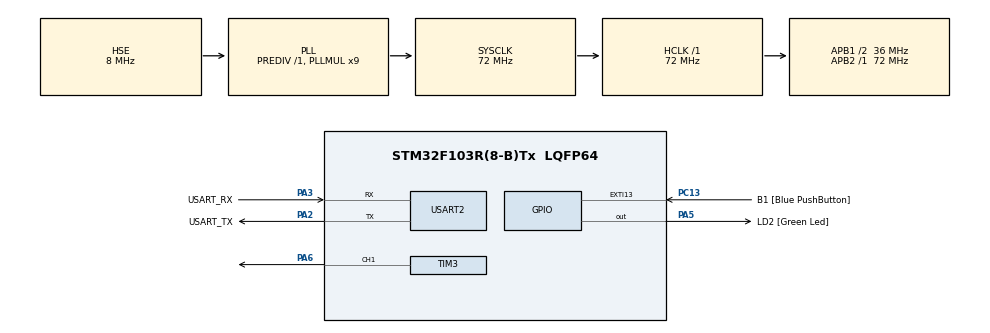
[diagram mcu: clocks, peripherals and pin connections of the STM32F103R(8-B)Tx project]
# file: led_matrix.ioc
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Dma.Request0=TIM3_CH1/TRIG
Dma.TIM3_CH1/TRIG.0.Direction=DMA_MEMORY_TO_PERIPH
Dma.TIM3_CH1/TRIG.0.Instance=DMA1_Channel6
Dma.TIM3_CH1/TRIG.0.MemDataAlignment=DMA_MDATAALIGN_BYTE
Dma.TIM3_CH1/TRIG.0.MemInc=DMA_MINC_ENABLE
Dma.TIM3_CH1/TRIG.0.Mode=DMA_NORMAL
Dma.TIM3_CH1/TRIG.0.PeriphDataAlignment=DMA_PDATAALIGN_HALFWORD
Dma.TIM3_CH1/TRIG.0.PeriphInc=DMA_PINC_DISABLE
Dma.TIM3_CH1/TRIG.0.Priority=DMA_PRIORITY_LOW
Mcu.Family=STM32F1
Mcu.Name=STM32F103R(8-B)Tx
Mcu.Package=LQFP64
NVIC.DMA1_Channel6_IRQn=true\:0\:0\:false\:false\:true\:false\:true\:true
NVIC.EXTI15_10_IRQn=true\:0\:0\:false\:false\:true\:true\:true\:true
NVIC.PriorityGroup=NVIC_PRIORITYGROUP_4
NimaLTD.I-CUBE-WS28XX.3.0.1.DriverJjWS28XX=true
PA13.GPIO_Label=TMS
PA13.Mode=Serial_Wire
PA13.Signal=SYS_JTMS-SWDIO
PA14.GPIO_Label=TCK
PA14.Mode=Serial_Wire
PA14.Signal=SYS_JTCK-SWCLK
PA2.GPIO_Label=USART_TX
PA2.GPIO_Mode=GPIO_MODE_AF_PP
PA2.GPIO_PuPd=GPIO_NOPULL
PA2.GPIO_Speed=GPIO_SPEED_FREQ_LOW
PA2.Mode=Asynchronous
PA2.Signal=USART2_TX
PA3.GPIO_Label=USART_RX
PA3.GPIO_Mode=GPIO_MODE_AF_PP
PA3.GPIO_PuPd=GPIO_NOPULL
PA3.GPIO_Speed=GPIO_SPEED_FREQ_LOW
PA3.Mode=Asynchronous
PA3.Signal=USART2_RX
PA5.GPIO_Label=LD2 [Green Led]
PA5.GPIO_ModeDefaultOutputPP=GPIO_MODE_OUTPUT_PP
PA5.GPIO_PuPd=GPIO_NOPULL
PA5.GPIO_Speed=GPIO_SPEED_FREQ_LOW
PA5.Signal=GPIO_Output
PA6.Signal=S_TIM3_CH1
PB3.GPIO_Label=SWO
PB3.Signal=SYS_JTDO-TRACESWO
PC13-TAMPER-RTC.GPIO_Label=B1 [Blue PushButton]
PC13-TAMPER-RTC.GPIO_PuPd=GPIO_NOPULL
PC13-TAMPER-RTC.Signal=GPXTI13
PC14-OSC32_IN.Mode=LSE-External-Oscillator
PC14-OSC32_IN.Signal=RCC_OSC32_IN
PC15-OSC32_OUT.Mode=LSE-External-Oscillator
PC15-OSC32_OUT.Signal=RCC_OSC32_OUT
PD0-OSC_IN.Mode=HSE-External-Clock-Source
PD0-OSC_IN.Signal=RCC_OSC_IN
PD1-OSC_OUT.Mode=HSE-External-Clock-Source
PD1-OSC_OUT.Signal=RCC_OSC_OUT
ProjectManager.HeapSize=0x200
ProjectManager.StackSize=0x400
ProjectManager.TargetToolchain=STM32CubeIDE
RCC.AHBFreq_Value=72000000
RCC.APB1CLKDivider=RCC_HCLK_DIV2
RCC.APB1Freq_Value=36000000
RCC.APB1TimFreq_Value=72000000
RCC.APB2Freq_Value=72000000
RCC.APB2TimFreq_Value=72000000
RCC.HCLKFreq_Value=72000000
RCC.PLLMUL=RCC_PLL_MUL9
RCC.PLLSourceVirtual=RCC_PLLSOURCE_HSE
RCC.RTCClockSelection=RCC_RTCCLKSOURCE_LSE
RCC.SYSCLKFreq_VALUE=72000000
RCC.SYSCLKSource=RCC_SYSCLKSOURCE_PLLCLK
RCC.USBFreq_Value=72000000
SH.S_TIM3_CH1.0=TIM3_CH1,PWM Generation1 CH1
TIM3.Channel-PWM\ Generation1\ CH1=TIM_CHANNEL_1
USART2.VirtualMode=VM_ASYNC
VP_NimaLTD.I-CUBE-WS28XX_VS_DriverJjWS28XX_1.0.0_3.0.1.Mode=DriverJjWS28XX
VP_TIM3_VS_ClockSourceINT.Mode=Internal
board=NUCLEO-F103RB

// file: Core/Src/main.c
/* USER CODE BEGIN Header */
/**
  ******************************************************************************
  * @file           : main.c
  * @brief          : Main program body
  ******************************************************************************
  * @attention
  *
  * Copyright (c) 2024 STMicroelectronics.
  * All rights reserved.
  *
  ******************************************************************************
  */
/* USER CODE END Header */
#include "main.h"
#include "dma.h"
#include "tim.h"
#include "usart.h"
#include "gpio.h"

/* USER CODE BEGIN Includes */
#include "ws28xx.h"
/* USER CODE END Includes */

#define LED_ROWS 8
#define LED_COLS 32
#define DELAY_TIME 50  // Faster shifting delay

WS28XX_HandleTypeDef ws;

/* Function to calculate the correct LED index based on the zig-zag pattern */
int Get_LED_Index(int row, int col) {
    if (row % 2 == 0) {
        // Even row (left-to-right)
        return (row * LED_COLS / 2) + col;
    } else {
        // Odd row (right-to-left)
        return (row * LED_COLS / 2) + (LED_COLS / 2 - 1 - col);
    }
}

/* Function to draw the arrow */
void Draw_Arrow(WS28XX_HandleTypeDef *ws, int *arrow, int color, int brightness) {
    for (int i = 0; i < 26; i++) {
        // Ensure arrow doesn't affect the first 2 rows or last 2 rows of the LED matrix (top and bottom strips)
        if (arrow[i] >= 16 && arrow[i] <= 239) {
            WS28XX_SetPixel_RGBW_565(ws, arrow[i], color, brightness);  // Only set pixels between the top and bottom strips
        }
    }
    WS28XX_Update(ws);  // Update the matrix to display the arrow
}

/* Function to clear the arrow */
void Clear_Arrow(WS28XX_HandleTypeDef *ws, int *arrow) {
    for (int i = 0; i < 26; i++) {
        if (arrow[i] >= 16 && arrow[i] <= 239) {
            WS28XX_SetPixel_RGBW_565(ws, arrow[i], COLOR_RGB565_BLACK, 0);  // Clear the arrow LEDs between the top and bottom strips
        }
    }
    WS28XX_Update(ws);  // Update the matrix to clear the arrow
}

/* Function to shift the arrow forward */
void Shift_Arrow(int *arrow) {
    for (int i = 0; i < 26; i++) {
        arrow[i] = arrow[i] + 8;  // Shifting each LED forward by one row (8 LEDs in each row)
        if (arrow[i] >= 240) {  // Reset the arrow to the starting position (after the bottom strip)
            arrow[i] = arrow[i] % (LED_ROWS * LED_COLS - 16);  // Ensure the arrow stays between rows 2 to 6
        }
    }
}

/* Function to draw the top and bottom strips */
void Draw_Strips(WS28XX_HandleTypeDef *ws, int color, int brightness) {
    // Top strip (LEDs from 240 to 255)
    for (int i = 240; i <= 255; i++) {
        WS28XX_SetPixel_RGBW_565(ws, i, color, brightness);
    }

    // Bottom strip (LEDs from 0 to 15)
    for (int i = 0; i <= 15; i++) {
        WS28XX_SetPixel_RGBW_565(ws, i, color, brightness);
    }

    WS28XX_Update(ws);  // Update the matrix to display the strips
}

/* Function to update brightness for both arrow and strips */
void Update_Brightness(WS28XX_HandleTypeDef *ws, int arrow_brightness, int strip_brightness) {
    // Arrow shape LED indices
    int arrow[] = {
        83, 84, 91, 92, 99, 100, 107, 108, 115, 116, 123, 124,
        131, 132, 137, 138, 139, 140, 141, 142, 146, 147, 148, 149,
        155, 156
    };

    // Update brightness for the arrow
    Draw_Arrow(ws, arrow, COLOR_RGB565_GREEN, arrow_brightness);

    // Update brightness for the strips
    Draw_Strips(ws, COLOR_RGB565_CYAN, strip_brightness);
}

/* The application entry point. */
int main(void) {
  /* MCU Configuration--------------------------------------------------------*/

  HAL_Init();
  SystemClock_Config();

  MX_GPIO_Init();
  MX_DMA_Init();
  MX_USART2_UART_Init();
  MX_TIM3_Init();

  WS28XX_Init(&ws, &htim3, 72, TIM_CHANNEL_1, 256);  // Initialize with total LEDs set to 256

  /* Arrow shape LED indices */
  int arrow[] = {
      83, 84, 91, 92, 99, 100, 107, 108, 115, 116, 123, 124,
      131, 132, 137, 138, 139, 140, 141, 142, 146, 147, 148, 149,
      155, 156
  };

  /* Draw the strips once, keeping them constant */
  Draw_Strips(&ws, COLOR_RGB565_CYAN, 255);  // Max brightness for strips

  /* Infinite loop */
  while (1) {
    // Clear the arrow from its previous position
    Clear_Arrow(&ws, arrow);

    // Shift the arrow to the next position
    Shift_Arrow(arrow);

    // Draw the arrow with adjustable brightness, keeping strips constant
    Draw_Arrow(&ws, arrow, COLOR_RGB565_GREEN, 255);  // Max brightness for the arrow

    HAL_Delay(DELAY_TIME);  // Adjust the delay as per your speed requirement
  }
}

void SystemClock_Config(void)
{
  RCC_OscInitTypeDef RCC_OscInitStruct = {0};
  RCC_ClkInitTypeDef RCC_ClkInitStruct = {0};

  RCC_OscInitStruct.OscillatorType = RCC_OSCILLATORTYPE_HSE;
  RCC_OscInitStruct.HSEState = RCC_HSE_BYPASS;
  RCC_OscInitStruct.HSEPredivValue = RCC_HSE_PREDIV_DIV1;
  RCC_OscInitStruct.HSIState = RCC_HSI_ON;
  RCC_OscInitStruct.PLL.PLLState = RCC_PLL_ON;
  RCC_OscInitStruct.PLL.PLLSource = RCC_PLLSOURCE_HSE;
  RCC_OscInitStruct.PLL.PLLMUL = RCC_PLL_MUL9;
  if (HAL_RCC_OscConfig(&RCC_OscInitStruct) != HAL_OK)
  {
    Error_Handler();
  }

  RCC_ClkInitStruct.ClockType = RCC_CLOCKTYPE_HCLK|RCC_CLOCKTYPE_SYSCLK
                              |RCC_CLOCKTYPE_PCLK1|RCC_CLOCKTYPE_PCLK2;
  RCC_ClkInitStruct.SYSCLKSource = RCC_SYSCLKSOURCE_PLLCLK;
  RCC_ClkInitStruct.AHBCLKDivider = RCC_SYSCLK_DIV1;
  RCC_ClkInitStruct.APB1CLKDivider = RCC_HCLK_DIV2;
  RCC_ClkInitStruct.APB2CLKDivider = RCC_HCLK_DIV1;

  if (HAL_RCC_ClockConfig(&RCC_ClkInitStruct, FLASH_LATENCY_2) != HAL_OK)
  {
    Error_Handler();
  }
}

/**
  * @brief Error Handler
  * @retval None
  */
void Error_Handler(void)
{
  __disable_irq();
  while (1)
  {
  }
}
